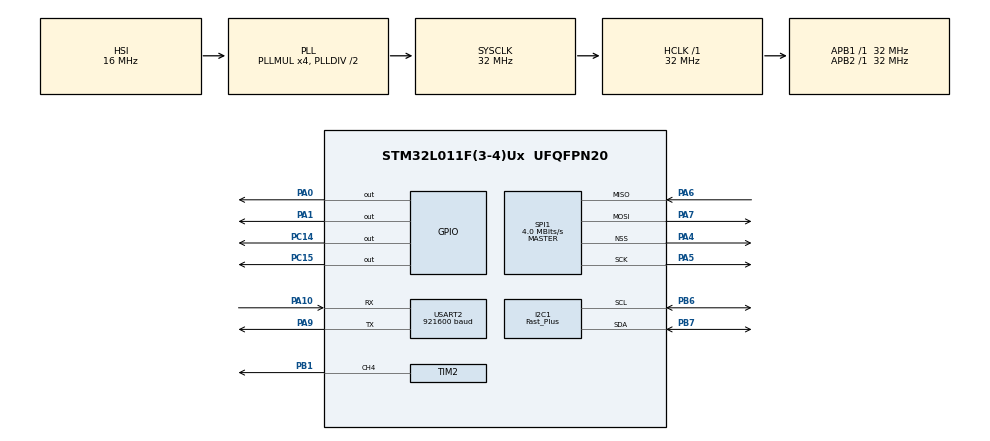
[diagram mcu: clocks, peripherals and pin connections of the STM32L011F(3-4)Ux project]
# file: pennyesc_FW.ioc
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I2C1.I2C_Speed_Mode=I2C_Fast_Plus
I2C1.Timing=0x00100413
Mcu.Family=STM32L0
Mcu.Name=STM32L011F(3-4)Ux
Mcu.Package=UFQFPN20
PA0-CK_IN.Signal=GPIO_Output
PA1.Signal=GPIO_Output
PA10.Mode=Asynchronous
PA10.Signal=USART2_RX
PA13.Mode=Serial_Wire
PA13.Signal=SYS_SWDIO
PA14.Mode=Serial_Wire
PA14.Signal=SYS_SWCLK
PA4.Mode=NSS_Signal_Hard_Output
PA4.Signal=SPI1_NSS
PA5.Mode=Full_Duplex_Master
PA5.Signal=SPI1_SCK
PA6.Mode=Full_Duplex_Master
PA6.Signal=SPI1_MISO
PA7.Mode=Full_Duplex_Master
PA7.Signal=SPI1_MOSI
PA9.Mode=Asynchronous
PA9.Signal=USART2_TX
PB1.Signal=S_TIM2_CH4
PB6.Mode=I2C
PB6.Signal=I2C1_SCL
PB7.Mode=I2C
PB7.Signal=I2C1_SDA
PC14-OSC32_IN.Signal=GPIO_Output
PC15-OSC32_OUT.Signal=GPIO_Output
ProjectManager.HeapSize=0x000
ProjectManager.StackSize=0x400
ProjectManager.TargetToolchain=STM32CubeIDE
RCC.ADCFreq_Value=16000000
RCC.AHBFreq_Value=32000000
RCC.APB1Freq_Value=32000000
RCC.APB1TimFreq_Value=32000000
RCC.APB2Freq_Value=32000000
RCC.APB2TimFreq_Value=32000000
RCC.HCLKFreq_Value=32000000
RCC.HSE_VALUE=8000000
RCC.HSI16_VALUE=16000000
RCC.HSI_VALUE=16000000
RCC.LSE_VALUE=32768
RCC.MSI_VALUE=2097000
RCC.PLLMUL=RCC_PLLMUL_4
RCC.SYSCLKFreq_VALUE=32000000
RCC.SYSCLKSource=RCC_SYSCLKSOURCE_PLLCLK
RCC.Usart2ClockSelection=RCC_USART2CLKSOURCE_SYSCLK
RCC.VCOOutputFreq_Value=64000000
SH.S_TIM2_CH4.0=TIM2_CH4,PWM Generation4 CH4
SPI1.BaudRatePrescaler=SPI_BAUDRATEPRESCALER_8
SPI1.CLKPhase=SPI_PHASE_2EDGE
SPI1.CalculateBaudRate=4.0 MBits/s
SPI1.DataSize=SPI_DATASIZE_16BIT
SPI1.Direction=SPI_DIRECTION_2LINES
SPI1.Mode=SPI_MODE_MASTER
SPI1.TIMode=SPI_TIMODE_DISABLE
SPI1.VirtualNSS=VM_NSSHARD
SPI1.VirtualType=VM_MASTER
TIM2.Channel-PWM\ Generation4\ CH4=TIM_CHANNEL_4
TIM2.Period=799
USART2.BaudRate=921600
USART2.VirtualMode-Asynchronous=VM_ASYNC
board=custom

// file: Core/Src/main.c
/* USER CODE BEGIN Header */
/**
  ******************************************************************************
  * @file           : main.c
  * @brief          : Main program body
  ******************************************************************************
  * @attention
  *
  * Copyright (c) 2025 STMicroelectronics.
  * All rights reserved.
  *
  * This software is licensed under terms that can be found in the LICENSE file
  * in the root directory of this software component.
  * If no LICENSE file comes with this software, it is provided AS-IS.
  *
  ******************************************************************************
  */
/* USER CODE END Header */
#include "main.h"

I2C_HandleTypeDef hi2c1;

SPI_HandleTypeDef hspi1;

TIM_HandleTypeDef htim2;

UART_HandleTypeDef huart2;

void SystemClock_Config(void);
static void MX_GPIO_Init(void);
static void MX_USART2_UART_Init(void);
static void MX_SPI1_Init(void);
static void MX_I2C1_Init(void);
static void MX_TIM2_Init(void);

int main(void)
{

  /* MCU Configuration--------------------------------------------------------*/

  /* Reset of all peripherals, Initializes the Flash interface and the Systick. */
  HAL_Init();

  /* Configure the system clock */
  SystemClock_Config();

  /* Initialize all configured peripherals */
  MX_GPIO_Init();
  MX_USART2_UART_Init();
  MX_SPI1_Init();
  MX_I2C1_Init();
  MX_TIM2_Init();
  /* USER CODE BEGIN 2 */

  int counter = 0;

  /* USER CODE END 2 */

  /* Infinite loop */
  /* USER CODE BEGIN WHILE */
  while (1)
  {
	  counter++;
	  HAL_Delay(100);
    /* USER CODE END WHILE */

  }
}

void SystemClock_Config(void)
{
  RCC_OscInitTypeDef RCC_OscInitStruct = {0};
  RCC_ClkInitTypeDef RCC_ClkInitStruct = {0};
  RCC_PeriphCLKInitTypeDef PeriphClkInit = {0};

  /** Configure the main internal regulator output voltage
  */
  __HAL_PWR_VOLTAGESCALING_CONFIG(PWR_REGULATOR_VOLTAGE_SCALE1);

  /** Initializes the RCC Oscillators according to the specified parameters
  * in the RCC_OscInitTypeDef structure.
  */
  RCC_OscInitStruct.OscillatorType = RCC_OSCILLATORTYPE_HSI;
  RCC_OscInitStruct.HSIState = RCC_HSI_ON;
  RCC_OscInitStruct.HSICalibrationValue = RCC_HSICALIBRATION_DEFAULT;
  RCC_OscInitStruct.PLL.PLLState = RCC_PLL_ON;
  RCC_OscInitStruct.PLL.PLLSource = RCC_PLLSOURCE_HSI;
  RCC_OscInitStruct.PLL.PLLMUL = RCC_PLLMUL_4;
  RCC_OscInitStruct.PLL.PLLDIV = RCC_PLLDIV_2;
  if (HAL_RCC_OscConfig(&RCC_OscInitStruct) != HAL_OK)
  {
    Error_Handler();
  }

  /** Initializes the CPU, AHB and APB buses clocks
  */
  RCC_ClkInitStruct.ClockType = RCC_CLOCKTYPE_HCLK|RCC_CLOCKTYPE_SYSCLK
                              |RCC_CLOCKTYPE_PCLK1|RCC_CLOCKTYPE_PCLK2;
  RCC_ClkInitStruct.SYSCLKSource = RCC_SYSCLKSOURCE_PLLCLK;
  RCC_ClkInitStruct.AHBCLKDivider = RCC_SYSCLK_DIV1;
  RCC_ClkInitStruct.APB1CLKDivider = RCC_HCLK_DIV1;
  RCC_ClkInitStruct.APB2CLKDivider = RCC_HCLK_DIV1;

  if (HAL_RCC_ClockConfig(&RCC_ClkInitStruct, FLASH_LATENCY_1) != HAL_OK)
  {
    Error_Handler();
  }
  PeriphClkInit.PeriphClockSelection = RCC_PERIPHCLK_USART2|RCC_PERIPHCLK_I2C1;
  PeriphClkInit.Usart2ClockSelection = RCC_USART2CLKSOURCE_SYSCLK;
  PeriphClkInit.I2c1ClockSelection = RCC_I2C1CLKSOURCE_PCLK1;
  if (HAL_RCCEx_PeriphCLKConfig(&PeriphClkInit) != HAL_OK)
  {
    Error_Handler();
  }
}

static void MX_I2C1_Init(void)
{

  hi2c1.Instance = I2C1;
  hi2c1.Init.Timing = 0x00100413;
  hi2c1.Init.OwnAddress1 = 0;
  hi2c1.Init.AddressingMode = I2C_ADDRESSINGMODE_7BIT;
  hi2c1.Init.DualAddressMode = I2C_DUALADDRESS_DISABLE;
  hi2c1.Init.OwnAddress2 = 0;
  hi2c1.Init.OwnAddress2Masks = I2C_OA2_NOMASK;
  hi2c1.Init.GeneralCallMode = I2C_GENERALCALL_DISABLE;
  hi2c1.Init.NoStretchMode = I2C_NOSTRETCH_DISABLE;
  if (HAL_I2C_Init(&hi2c1) != HAL_OK)
  {
    Error_Handler();
  }

  /** Configure Analogue filter
  */
  if (HAL_I2CEx_ConfigAnalogFilter(&hi2c1, I2C_ANALOGFILTER_ENABLE) != HAL_OK)
  {
    Error_Handler();
  }

  /** Configure Digital filter
  */
  if (HAL_I2CEx_ConfigDigitalFilter(&hi2c1, 0) != HAL_OK)
  {
    Error_Handler();
  }

  /** I2C Fast mode Plus enable
  */
  HAL_I2CEx_EnableFastModePlus(I2C_FASTMODEPLUS_I2C1);

}

static void MX_SPI1_Init(void)
{

  /* SPI1 parameter configuration*/
  hspi1.Instance = SPI1;
  hspi1.Init.Mode = SPI_MODE_MASTER;
  hspi1.Init.Direction = SPI_DIRECTION_2LINES;
  hspi1.Init.DataSize = SPI_DATASIZE_16BIT;
  hspi1.Init.CLKPolarity = SPI_POLARITY_LOW;
  hspi1.Init.CLKPhase = SPI_PHASE_2EDGE;
  hspi1.Init.NSS = SPI_NSS_HARD_OUTPUT;
  hspi1.Init.BaudRatePrescaler = SPI_BAUDRATEPRESCALER_8;
  hspi1.Init.FirstBit = SPI_FIRSTBIT_MSB;
  hspi1.Init.TIMode = SPI_TIMODE_DISABLE;
  hspi1.Init.CRCCalculation = SPI_CRCCALCULATION_DISABLE;
  hspi1.Init.CRCPolynomial = 7;
  if (HAL_SPI_Init(&hspi1) != HAL_OK)
  {
    Error_Handler();
  }

}

static void MX_TIM2_Init(void)
{

  TIM_MasterConfigTypeDef sMasterConfig = {0};
  TIM_OC_InitTypeDef sConfigOC = {0};

  htim2.Instance = TIM2;
  htim2.Init.Prescaler = 0;
  htim2.Init.CounterMode = TIM_COUNTERMODE_UP;
  htim2.Init.Period = 799;
  htim2.Init.ClockDivision = TIM_CLOCKDIVISION_DIV1;
  htim2.Init.AutoReloadPreload = TIM_AUTORELOAD_PRELOAD_DISABLE;
  if (HAL_TIM_PWM_Init(&htim2) != HAL_OK)
  {
    Error_Handler();
  }
  sMasterConfig.MasterOutputTrigger = TIM_TRGO_RESET;
  sMasterConfig.MasterSlaveMode = TIM_MASTERSLAVEMODE_DISABLE;
  if (HAL_TIMEx_MasterConfigSynchronization(&htim2, &sMasterConfig) != HAL_OK)
  {
    Error_Handler();
  }
  sConfigOC.OCMode = TIM_OCMODE_PWM1;
  sConfigOC.Pulse = 0;
  sConfigOC.OCPolarity = TIM_OCPOLARITY_HIGH;
  sConfigOC.OCFastMode = TIM_OCFAST_DISABLE;
  if (HAL_TIM_PWM_ConfigChannel(&htim2, &sConfigOC, TIM_CHANNEL_4) != HAL_OK)
  {
    Error_Handler();
  }
  HAL_TIM_MspPostInit(&htim2);

}

static void MX_USART2_UART_Init(void)
{

  huart2.Instance = USART2;
  huart2.Init.BaudRate = 921600;
  huart2.Init.WordLength = UART_WORDLENGTH_8B;
  huart2.Init.StopBits = UART_STOPBITS_1;
  huart2.Init.Parity = UART_PARITY_NONE;
  huart2.Init.Mode = UART_MODE_TX_RX;
  huart2.Init.HwFlowCtl = UART_HWCONTROL_NONE;
  huart2.Init.OverSampling = UART_OVERSAMPLING_16;
  huart2.Init.OneBitSampling = UART_ONE_BIT_SAMPLE_DISABLE;
  huart2.AdvancedInit.AdvFeatureInit = UART_ADVFEATURE_NO_INIT;
  if (HAL_UART_Init(&huart2) != HAL_OK)
  {
    Error_Handler();
  }

}

static void MX_GPIO_Init(void)
{
  GPIO_InitTypeDef GPIO_InitStruct = {0};

  /* GPIO Ports Clock Enable */
  __HAL_RCC_GPIOC_CLK_ENABLE();
  __HAL_RCC_GPIOA_CLK_ENABLE();
  __HAL_RCC_GPIOB_CLK_ENABLE();

  /*Configure GPIO pin Output Level */
  HAL_GPIO_WritePin(GPIOC, GPIO_PIN_14|GPIO_PIN_15, GPIO_PIN_RESET);

  /*Configure GPIO pin Output Level */
  HAL_GPIO_WritePin(GPIOA, GPIO_PIN_0|GPIO_PIN_1, GPIO_PIN_RESET);

  /*Configure GPIO pins : PC14 PC15 */
  GPIO_InitStruct.Pin = GPIO_PIN_14|GPIO_PIN_15;
  GPIO_InitStruct.Mode = GPIO_MODE_OUTPUT_PP;
  GPIO_InitStruct.Pull = GPIO_NOPULL;
  GPIO_InitStruct.Speed = GPIO_SPEED_FREQ_LOW;
  HAL_GPIO_Init(GPIOC, &GPIO_InitStruct);

  /*Configure GPIO pins : PA0 PA1 */
  GPIO_InitStruct.Pin = GPIO_PIN_0|GPIO_PIN_1;
  GPIO_InitStruct.Mode = GPIO_MODE_OUTPUT_PP;
  GPIO_InitStruct.Pull = GPIO_NOPULL;
  GPIO_InitStruct.Speed = GPIO_SPEED_FREQ_LOW;
  HAL_GPIO_Init(GPIOA, &GPIO_InitStruct);

}

void Error_Handler(void)
{
  __disable_irq();
  while (1)
  {
  }
}
